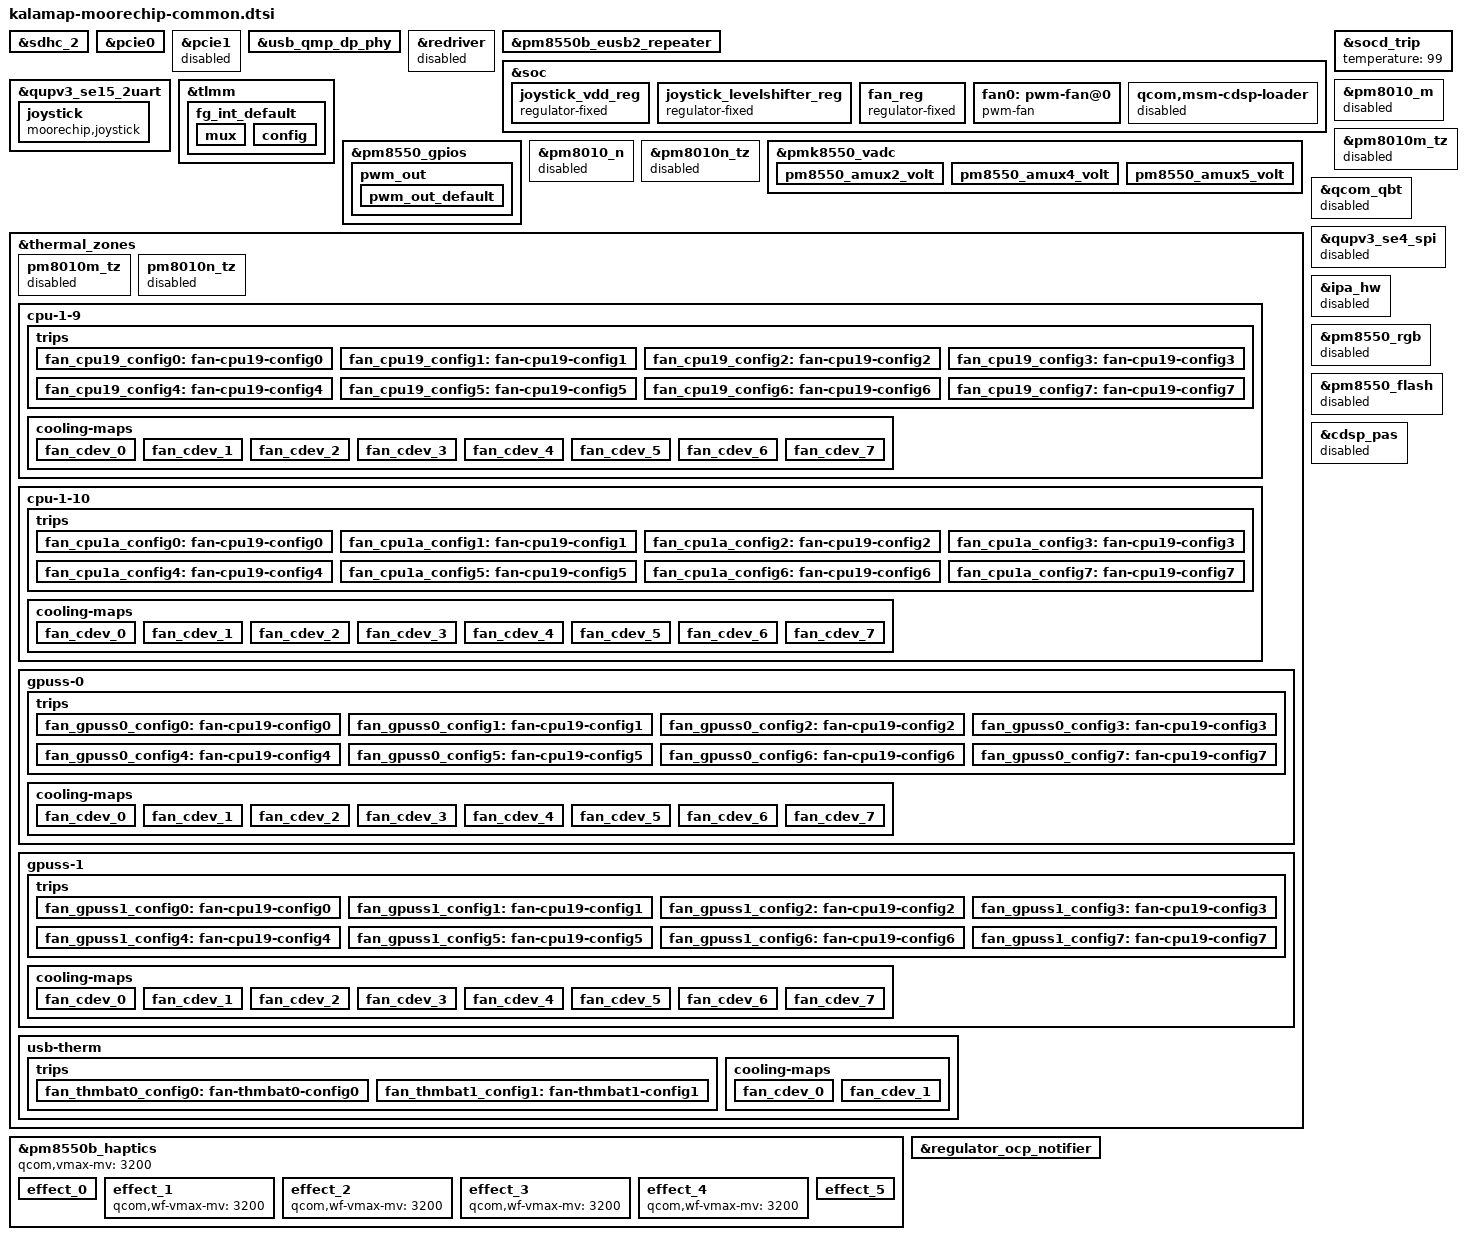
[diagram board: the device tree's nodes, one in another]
#include "../qcom/kalama-qrd.dtsi"

&sdhc_2 {
	cd-gpios = <&pm8550_gpios 12 GPIO_ACTIVE_HIGH>;
	cd-debounce-delay-ms = <2000>;

	qcom,msm-bus,name = "sdhc2";
	qcom,msm-bus,num-cases = <7>;
	qcom,msm-bus,num-paths = <2>;
	qcom,msm-bus,vectors-KBps =
		/* No Vote */
		<0 0>, <0 0>,
		/* 400 KB/s*/
		<1046 3200>, <1600 1600>,
		/* 25 MB/s */
		<65360 250000>, <100000 133320>,
		/* 50 MB/s */
		<130718 250000>, <133320 133320>,
		/* 100 MB/s */
		<261438 250000>, <150000 133320>,
		/* 200 MB/s */
		<261438 800000>, <300000 300000>,
		/* Max. bandwidth */
		<1338562 4096000>, <1338562 4096000>;
	qcom,bus-bw-vectors-bps = <0 400000 25000000 50000000
		100000000 200000000 4294967295>;
};

&pcie0 {
	qcom,config-recovery;
	qcom,drv-name = "lpass";
	msi-map = <0x0 &gic_its 0x1400 0x1>,
		  <0x100 &gic_its 0x1401 0x1>; /* 32 event IDs */
};

&pcie1 {
	status = "disabled";
};

&usb_qmp_dp_phy {
	pinctrl-names = "default";
};

&redriver {
	status = "disabled";
};

&pm8550b_eusb2_repeater {
	qcom,param-override-seq =
		/* <value reg_offset> */
		/* Adjust HS trasmit amplitude */
		<0xb 0x51
		/* Squelch detection threshold */
		 0x3 0x54
		/* Tx pre-emphasis tuning */
		 0x3 0x57
		/* HS disconnect threshold */
		 0x6 0x53>;
};

&soc {
	joystick_vdd_reg: joystick_vdd_reg {
		compatible = "regulator-fixed";
		regulator-name = "joystick_vdd_reg";
		regulator-min-microvolt = <3300000>;
		regulator-max-microvolt = <3300000>;
		enable-active-high;
		gpio = <&tlmm 99 GPIO_ACTIVE_HIGH>;
	};

	// AW3911
	joystick_levelshifter_reg: joystick_levelshifter_reg {
		compatible = "regulator-fixed";
		regulator-name = "joystick_levelshifter_reg";
		regulator-min-microvolt = <1800000>;
		regulator-max-microvolt = <1800000>;
		enable-active-high;
		gpio = <&tlmm 12 GPIO_ACTIVE_HIGH>;
	};
};

&qupv3_se15_2uart {
	status = "okay";

	joystick: joystick {
		status = "okay";
		compatible = "moorechip,joystick";
		vdd-supply = <&joystick_vdd_reg>;
		levelshifter-supply = <&joystick_levelshifter_reg>;

		moorechip,boot-gpio = <&tlmm 1 GPIO_ACTIVE_LOW>;
		moorechip,reset-gpio = <&tlmm 0 GPIO_ACTIVE_LOW>;
	};
};

&tlmm {
	fg_int_default: fg_int_default {
		mux {
			pins = "gpio13";
			function = "gpio";
		};
		config {
			pins = "gpio13";
			drive_strength = <2>;
			bias-disable;
		};
	};
};

&soc {
	fan_reg: fan_reg {
		compatible = "regulator-fixed";
		regulator-name = "fan_reg";
		regulator-min-microvolt = <5000000>;
		regulator-max-microvolt = <5000000>;
		enable-active-high;
		gpio = <&tlmm 109 GPIO_ACTIVE_HIGH>;
	};
};

&pm8550_gpios {
	pwm_out {
		pwm_out_default: pwm_out_default {
			pins = "gpio8";
			function = "func1";
			input-disable;
			output-enable;
			output-low;
			bias-disable;
			power-source = <1>;
		};
	};
};

&soc {
	fan0: pwm-fan@0 {
		compatible = "pwm-fan";
		status = "ok";
		pwms = <&pm8550_pwm_2 0 50000>;
		cooling-levels = <0 40 65 75 90 100 120 150 175>;
		pinctrl-names = "default","fg_int";
		pinctrl-0 = <&pwm_out_default>;
		pinctrl-1 = <&fg_int_default>;
		fan-supply = <&fan_reg>;
		interrupt-parent = <&tlmm>;
		interrupts = <13 0x2004>;
		interrupt-names = "fg_int";
		pulses-per-revolution = <4>;
	};
};

&socd_trip {
	temperature = <99>;
};

&pm8010_m {
	status = "disabled";
};

&pm8010m_tz {
	status = "disabled";
};

&pm8010_n {
	status = "disabled";
};

&pm8010n_tz {
	status = "disabled";
};

&pmk8550_vadc {
	/delete-node/ pm8550_msm_therm;
	/delete-node/ pm8550_cam_flash_therm;
	/delete-node/ pm8550_wlan_therm;
	/delete-node/ pm8550_pa_therm_1;
	/delete-node/ pm8550_rear_tof_therm;

	pm8550_amux2_volt {
		reg = <PM8550_ADC5_GEN3_AMUX_THM2>;
		label = "pm8550_amux2_volt";
		qcom,pre-scaling = <1 1>;
	};

	pm8550_amux4_volt {
		reg = <PM8550_ADC5_GEN3_AMUX_THM4>;
		label = "pm8550_amux4_volt";
		qcom,pre-scaling = <1 1>;
	};

	pm8550_amux5_volt {
		reg = <PM8550_ADC5_GEN3_AMUX_THM5>;
		label = "pm8550_amux5_volt";
		qcom,pre-scaling = <1 1>;
	};
};

&thermal_zones {
	pm8010m_tz {
		status = "disabled";
	};

	pm8010n_tz {
		status = "disabled";
	};

	/delete-node/ skin-msm-therm;
	/delete-node/ cam-flash-therm;
	/delete-node/ wlan-therm;
	/delete-node/ pa-therm-1;
	/delete-node/ rear-tof-therm;

	cpu-1-9 {
		trips {
			fan_cpu19_config0: fan-cpu19-config0 {
				temperature = <50000>;
				hysteresis = <0>;
				type = "passive";
			};

			fan_cpu19_config1: fan-cpu19-config1 {
				temperature = <55000>;
				hysteresis = <0>;
				type = "passive";
			};

			fan_cpu19_config2: fan-cpu19-config2 {
				temperature = <60000>;
				hysteresis = <0>;
				type = "passive";
			};

			fan_cpu19_config3: fan-cpu19-config3 {
				temperature = <65000>;
				hysteresis = <0>;
				type = "passive";
			};

			fan_cpu19_config4: fan-cpu19-config4 {
				temperature = <70000>;
				hysteresis = <0>;
				type = "passive";
			};

			fan_cpu19_config5: fan-cpu19-config5 {
				temperature = <75000>;
				hysteresis = <0>;
				type = "passive";
			};

			fan_cpu19_config6: fan-cpu19-config6 {
				temperature = <80000>;
				hysteresis = <0>;
				type = "passive";
			};

			fan_cpu19_config7: fan-cpu19-config7 {
				temperature = <85000>;
				hysteresis = <0>;
				type = "passive";
			};
		};

		cooling-maps {
			fan_cdev_0 {
				trip = <&fan_cpu19_config0>;
				cooling-device = <&fan0 0 1>;
			};

			fan_cdev_1 {
				trip = <&fan_cpu19_config1>;
				cooling-device = <&fan0 1 2>;
			};

			fan_cdev_2 {
				trip = <&fan_cpu19_config2>;
				cooling-device = <&fan0 2 3>;
			};

			fan_cdev_3 {
				trip = <&fan_cpu19_config3>;
				cooling-device = <&fan0 3 4>;
			};

			fan_cdev_4 {
				trip = <&fan_cpu19_config4>;
				cooling-device = <&fan0 4 5>;
			};

			fan_cdev_5 {
				trip = <&fan_cpu19_config5>;
				cooling-device = <&fan0 5 6>;
			};

			fan_cdev_6 {
				trip = <&fan_cpu19_config6>;
				cooling-device = <&fan0 6 7>;
			};

			fan_cdev_7 {
				trip = <&fan_cpu19_config7>;
				cooling-device = <&fan0 7 8>;
			};
		};
	};



	cpu-1-10 {
		trips {
			fan_cpu1a_config0: fan-cpu19-config0 {
				temperature = <50000>;
				hysteresis = <0>;
				type = "passive";
			};

			fan_cpu1a_config1: fan-cpu19-config1 {
				temperature = <55000>;
				hysteresis = <0>;
				type = "passive";
			};

			fan_cpu1a_config2: fan-cpu19-config2 {
				temperature = <60000>;
				hysteresis = <0>;
				type = "passive";
			};

			fan_cpu1a_config3: fan-cpu19-config3 {
				temperature = <65000>;
				hysteresis = <0>;
				type = "passive";
			};

			fan_cpu1a_config4: fan-cpu19-config4 {
				temperature = <70000>;
				hysteresis = <0>;
				type = "passive";
			};

			fan_cpu1a_config5: fan-cpu19-config5 {
				temperature = <75000>;
				hysteresis = <0>;
				type = "passive";
			};

			fan_cpu1a_config6: fan-cpu19-config6 {
				temperature = <80000>;
				hysteresis = <0>;
				type = "passive";
			};

			fan_cpu1a_config7: fan-cpu19-config7 {
				temperature = <85000>;
				hysteresis = <0>;
				type = "passive";
			};
		};

		cooling-maps {
			fan_cdev_0 {
				trip = <&fan_cpu1a_config0>;
				cooling-device = <&fan0 0 1>;
			};

			fan_cdev_1 {
				trip = <&fan_cpu1a_config1>;
				cooling-device = <&fan0 1 2>;
			};

			fan_cdev_2 {
				trip = <&fan_cpu1a_config2>;
				cooling-device = <&fan0 2 3>;
			};

			fan_cdev_3 {
				trip = <&fan_cpu1a_config3>;
				cooling-device = <&fan0 3 4>;
			};

			fan_cdev_4 {
				trip = <&fan_cpu1a_config4>;
				cooling-device = <&fan0 4 5>;
			};

			fan_cdev_5 {
				trip = <&fan_cpu1a_config5>;
				cooling-device = <&fan0 5 6>;
			};

			fan_cdev_6 {
				trip = <&fan_cpu1a_config6>;
				cooling-device = <&fan0 6 7>;
			};

			fan_cdev_7 {
				trip = <&fan_cpu1a_config7>;
				cooling-device = <&fan0 7 8>;
			};
		};
	};



	gpuss-0 {
		trips {
			fan_gpuss0_config0: fan-cpu19-config0 {
				temperature = <50000>;
				hysteresis = <0>;
				type = "passive";
			};

			fan_gpuss0_config1: fan-cpu19-config1 {
				temperature = <55000>;
				hysteresis = <0>;
				type = "passive";
			};

			fan_gpuss0_config2: fan-cpu19-config2 {
				temperature = <60000>;
				hysteresis = <0>;
				type = "passive";
			};

			fan_gpuss0_config3: fan-cpu19-config3 {
				temperature = <65000>;
				hysteresis = <0>;
				type = "passive";
			};

			fan_gpuss0_config4: fan-cpu19-config4 {
				temperature = <70000>;
				hysteresis = <0>;
				type = "passive";
			};

			fan_gpuss0_config5: fan-cpu19-config5 {
				temperature = <75000>;
				hysteresis = <0>;
				type = "passive";
			};

			fan_gpuss0_config6: fan-cpu19-config6 {
				temperature = <80000>;
				hysteresis = <0>;
				type = "passive";
			};

			fan_gpuss0_config7: fan-cpu19-config7 {
				temperature = <85000>;
				hysteresis = <0>;
				type = "passive";
			};
		};

		cooling-maps {
			fan_cdev_0 {
				trip = <&fan_gpuss0_config0>;
				cooling-device = <&fan0 0 1>;
			};

			fan_cdev_1 {
				trip = <&fan_gpuss0_config1>;
				cooling-device = <&fan0 1 2>;
			};

			fan_cdev_2 {
				trip = <&fan_gpuss0_config2>;
				cooling-device = <&fan0 2 3>;
			};

			fan_cdev_3 {
				trip = <&fan_gpuss0_config3>;
				cooling-device = <&fan0 3 4>;
			};

			fan_cdev_4 {
				trip = <&fan_gpuss0_config4>;
				cooling-device = <&fan0 4 5>;
			};

			fan_cdev_5 {
				trip = <&fan_gpuss0_config5>;
				cooling-device = <&fan0 5 6>;
			};

			fan_cdev_6 {
				trip = <&fan_gpuss0_config6>;
				cooling-device = <&fan0 6 7>;
			};

			fan_cdev_7 {
				trip = <&fan_gpuss0_config7>;
				cooling-device = <&fan0 7 8>;
			};
		};
	};

	gpuss-1 {
		trips {
			fan_gpuss1_config0: fan-cpu19-config0 {
				temperature = <50000>;
				hysteresis = <0>;
				type = "passive";
			};

			fan_gpuss1_config1: fan-cpu19-config1 {
				temperature = <55000>;
				hysteresis = <0>;
				type = "passive";
			};

			fan_gpuss1_config2: fan-cpu19-config2 {
				temperature = <60000>;
				hysteresis = <0>;
				type = "passive";
			};

			fan_gpuss1_config3: fan-cpu19-config3 {
				temperature = <65000>;
				hysteresis = <0>;
				type = "passive";
			};

			fan_gpuss1_config4: fan-cpu19-config4 {
				temperature = <70000>;
				hysteresis = <0>;
				type = "passive";
			};

			fan_gpuss1_config5: fan-cpu19-config5 {
				temperature = <75000>;
				hysteresis = <0>;
				type = "passive";
			};

			fan_gpuss1_config6: fan-cpu19-config6 {
				temperature = <80000>;
				hysteresis = <0>;
				type = "passive";
			};

			fan_gpuss1_config7: fan-cpu19-config7 {
				temperature = <85000>;
				hysteresis = <0>;
				type = "passive";
			};
		};

		cooling-maps {
			fan_cdev_0 {
				trip = <&fan_gpuss1_config0>;
				cooling-device = <&fan0 0 1>;
			};

			fan_cdev_1 {
				trip = <&fan_gpuss1_config1>;
				cooling-device = <&fan0 1 2>;
			};

			fan_cdev_2 {
				trip = <&fan_gpuss1_config2>;
				cooling-device = <&fan0 2 3>;
			};

			fan_cdev_3 {
				trip = <&fan_gpuss1_config3>;
				cooling-device = <&fan0 3 4>;
			};

			fan_cdev_4 {
				trip = <&fan_gpuss1_config4>;
				cooling-device = <&fan0 4 5>;
			};

			fan_cdev_5 {
				trip = <&fan_gpuss1_config5>;
				cooling-device = <&fan0 5 6>;
			};

			fan_cdev_6 {
				trip = <&fan_gpuss1_config6>;
				cooling-device = <&fan0 6 7>;
			};

			fan_cdev_7 {
				trip = <&fan_gpuss1_config7>;
				cooling-device = <&fan0 7 8>;
			};
		};
	};

	usb-therm {
		trips {
			fan_thmbat0_config0: fan-thmbat0-config0 {
				temperature = <43000>;
				hysteresis = <2000>;
				type = "passive";
			};

			fan_thmbat1_config1: fan-thmbat1-config1 {
				temperature = <45000>;
				hysteresis = <3000>;
				type = "passive";
			};
		};

		cooling-maps {
			fan_cdev_0 {
				trip = <&fan_thmbat0_config0>;
				cooling-device = <&fan0 6 7>;
			};

			fan_cdev_1 {
				trip = <&fan_thmbat1_config1>;
				cooling-device = <&fan0 7 8>;
			};
		};
	};
};

&pm8550b_haptics {
	status = "okay";
	qcom,vmax-mv = <3200>;

	effect_0 {
		/* CLICK */
		qcom,wf-pattern-data =  <0x15f  S_PERIOD_T_LRA  0>,
					<0x17f  S_PERIOD_T_LRA  0>,
					<0x19f  S_PERIOD_T_LRA  0>,
					<0x1df  S_PERIOD_T_LRA  0>,
					<0x1df  S_PERIOD_T_LRA  0>,
					<0x19f  S_PERIOD_T_LRA  0>,
					<0x17f  S_PERIOD_T_LRA  0>,
					<0x15f  S_PERIOD_T_LRA  0>;
		/delete-property/ qcom,wf-pattern-preload;
		qcom,wf-vmax-mv = <5000>;
	};

	effect_1 {
		/* DOUBLE_CLICK */
		qcom,wf-vmax-mv = <3200>;
	};

	effect_2 {
		/* TICK */
		qcom,wf-vmax-mv = <3200>;
	};

	effect_3 {
		/* THUD */
		qcom,wf-vmax-mv = <3200>;
	};

	effect_4 {
		/* POP */
		qcom,wf-vmax-mv = <3200>;
	};

	effect_5 {
		/* HEAVY CLICK */
		qcom,wf-pattern-data =  <0x11f  S_PERIOD_T_LRA  0>,
					<0x13f  S_PERIOD_T_LRA  0>,
					<0x15f  S_PERIOD_T_LRA  0>,
					<0x17f  S_PERIOD_T_LRA  0>,
					<0x17f  S_PERIOD_T_LRA  0>,
					<0x15f  S_PERIOD_T_LRA  0>,
					<0x13f  S_PERIOD_T_LRA  0>,
					<0x11f  S_PERIOD_T_LRA  0>;
		qcom,wf-vmax-mv = <5000>;
	};
};

&qcom_qbt {
	status = "disabled";
};

&qupv3_se4_spi {
	status = "disabled";
};

&ipa_hw {
	status = "disabled";
};

&regulator_ocp_notifier {
	/delete-property/ periph-bc3-supply;
	/delete-property/ periph-bc4-supply;
	/delete-property/ periph-bc5-supply;
	/delete-property/ periph-bc6-supply;
	/delete-property/ periph-bc7-supply;
};

&pm8550_rgb {
	status = "disabled";
};

&pm8550_flash {
	status = "disabled";
};

&cdsp_pas {
	status = "disabled";
};

&soc {
	qcom,msm-cdsp-loader {
		status = "disabled";
	};
};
